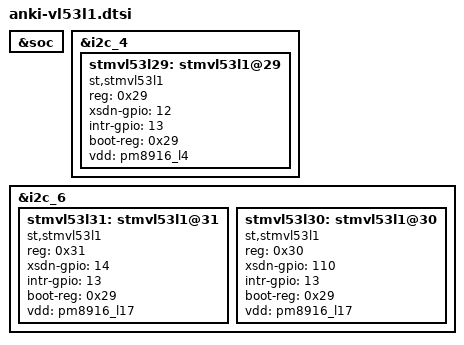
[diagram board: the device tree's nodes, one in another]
/*
 * Copyright (c) 2014-2015, The Linux Foundation. All rights reserved.
 *
 * This program is free software; you can redistribute it and/or modify
 * it under the terms of the GNU General Public License version 2 and
 * only version 2 as published by the Free Software Foundation.
 *
 * This program is distributed in the hope that it will be useful,
 * but WITHOUT ANY WARRANTY; without even the implied warranty of
 * MERCHANTABILITY or FITNESS FOR A PARTICULAR PURPOSE.  See the
 * GNU General Public License for more details.
 */

&soc {
};

&i2c_4 {
  status = "okay";

  // Spiderface configuration
  stmvl53l29: stmvl53l1@29 {
    compatible = "st,stmvl53l1";
    reg = <0x29>;
    xsdn-gpio = <12>;
    intr-gpio = <13>;
    boot-reg = <0x29>;
    vdd = <&pm8916_l4>;
  };
};

&i2c_6 {
  status = "okay";

  // Whiskey prototype configuration
  stmvl53l31: stmvl53l1@31 {
    compatible = "st,stmvl53l1";
    reg = <0x31>;
    xsdn-gpio = <14>;
    intr-gpio = <13>;
    boot-reg = <0x29>;
    vdd = <&pm8916_l17>;
  };
  stmvl53l30: stmvl53l1@30 {
    compatible = "st,stmvl53l1";
    reg = <0x30>;
    xsdn-gpio = <110>;
    intr-gpio = <13>;
    boot-reg = <0x29>;
    vdd = <&pm8916_l17>;
  };

};
